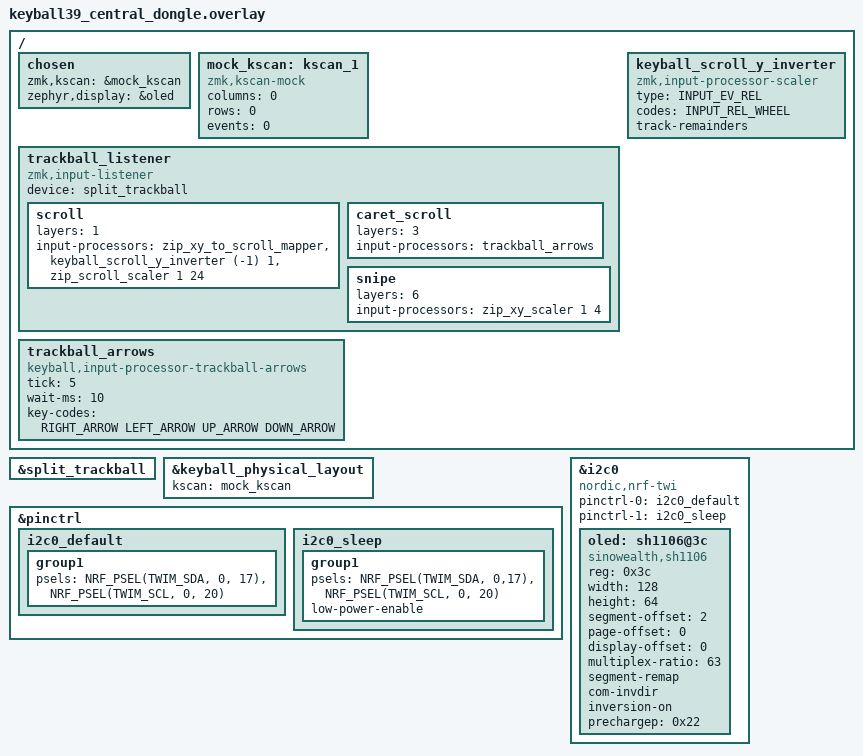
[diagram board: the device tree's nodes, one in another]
/*
 * Copyright (c) 2020 ZMK Contributors
 *
 * SPDX-License-Identifier: MIT
 */

#include "keyball39.dtsi"
#include "keyball39_esb.dtsi"
#include <dt-bindings/zmk/keys.h>
#include <zephyr/dt-bindings/input/input-event-codes.h>
#include <input/processors.dtsi>

/ {
    #address-cells = <1>;
    #size-cells = <0>;

    chosen {
        zmk,kscan = &mock_kscan;
        zephyr,display = &oled;
    };

    mock_kscan: kscan_1 {
        compatible = "zmk,kscan-mock";
        columns = <0>;
        rows = <0>;
        events = <0>;
    };

    trackball_listener {
        compatible = "zmk,input-listener";
        device = <&split_trackball>;

        scroll {
            layers = <1>;
            input-processors =
                <&zip_xy_to_scroll_mapper>,
                <&keyball_scroll_y_inverter (-1) 1>,
                <&zip_scroll_scaler 1 24>;
        };

        caret_scroll {
            layers = <3>;
            input-processors = <&trackball_arrows>;
        };

        snipe {
            layers = <6>;
            input-processors = <&zip_xy_scaler 1 4>;
        };
    };

    trackball_arrows: trackball_arrows {
        compatible = "keyball,input-processor-trackball-arrows";
        #input-processor-cells = <0>;
        tick = <5>;
        wait-ms = <10>;
        key-codes = <RIGHT_ARROW LEFT_ARROW UP_ARROW DOWN_ARROW>;
    };

    keyball_scroll_y_inverter: keyball_scroll_y_inverter {
        compatible = "zmk,input-processor-scaler";
        #input-processor-cells = <2>;
        type = <INPUT_EV_REL>;
        codes = <INPUT_REL_WHEEL>;
        track-remainders;
    };
};

&split_trackball {
    status = "okay";
};

&keyball_physical_layout {
    kscan = <&mock_kscan>;
};

&pinctrl {
    i2c0_default: i2c0_default {
        group1 {
            psels = <NRF_PSEL(TWIM_SDA, 0, 17)>,
                <NRF_PSEL(TWIM_SCL, 0, 20)>;
        };
    };

    i2c0_sleep: i2c0_sleep {
        group1 {
            psels = <NRF_PSEL(TWIM_SDA, 0,17)>,
                <NRF_PSEL(TWIM_SCL, 0, 20)>;
            low-power-enable;
        };
    };
};

&i2c0 {
    status = "okay";
    compatible = "nordic,nrf-twi";
    pinctrl-0 = <&i2c0_default>;
    pinctrl-1 = <&i2c0_sleep>;
    pinctrl-names = "default", "sleep";

    oled: sh1106@3c {
        compatible = "sinowealth,sh1106";
        reg = <0x3c>;
        width = <128>;
        height = <64>;
        segment-offset = <2>;
        page-offset = <0>;
        display-offset = <0>;
        multiplex-ratio = <63>;
        segment-remap;
        com-invdir;
        inversion-on;
        prechargep = <0x22>;
    };
};
